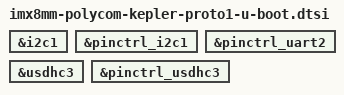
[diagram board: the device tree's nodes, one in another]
// SPDX-License-Identifier: GPL-2.0+
/*
 * u-boot-specific tags for kepler_proto1 (mirrors EVK's u-boot.dtsi pattern).
 */

#include "imx8mm-u-boot.dtsi"

&i2c1 {
	bootph-pre-ram;
};

&pinctrl_i2c1 {
	bootph-pre-ram;
};

&pinctrl_uart2 {
	bootph-pre-ram;
};

&usdhc3 {
	bootph-pre-ram;
};

&pinctrl_usdhc3 {
	bootph-pre-ram;
};
